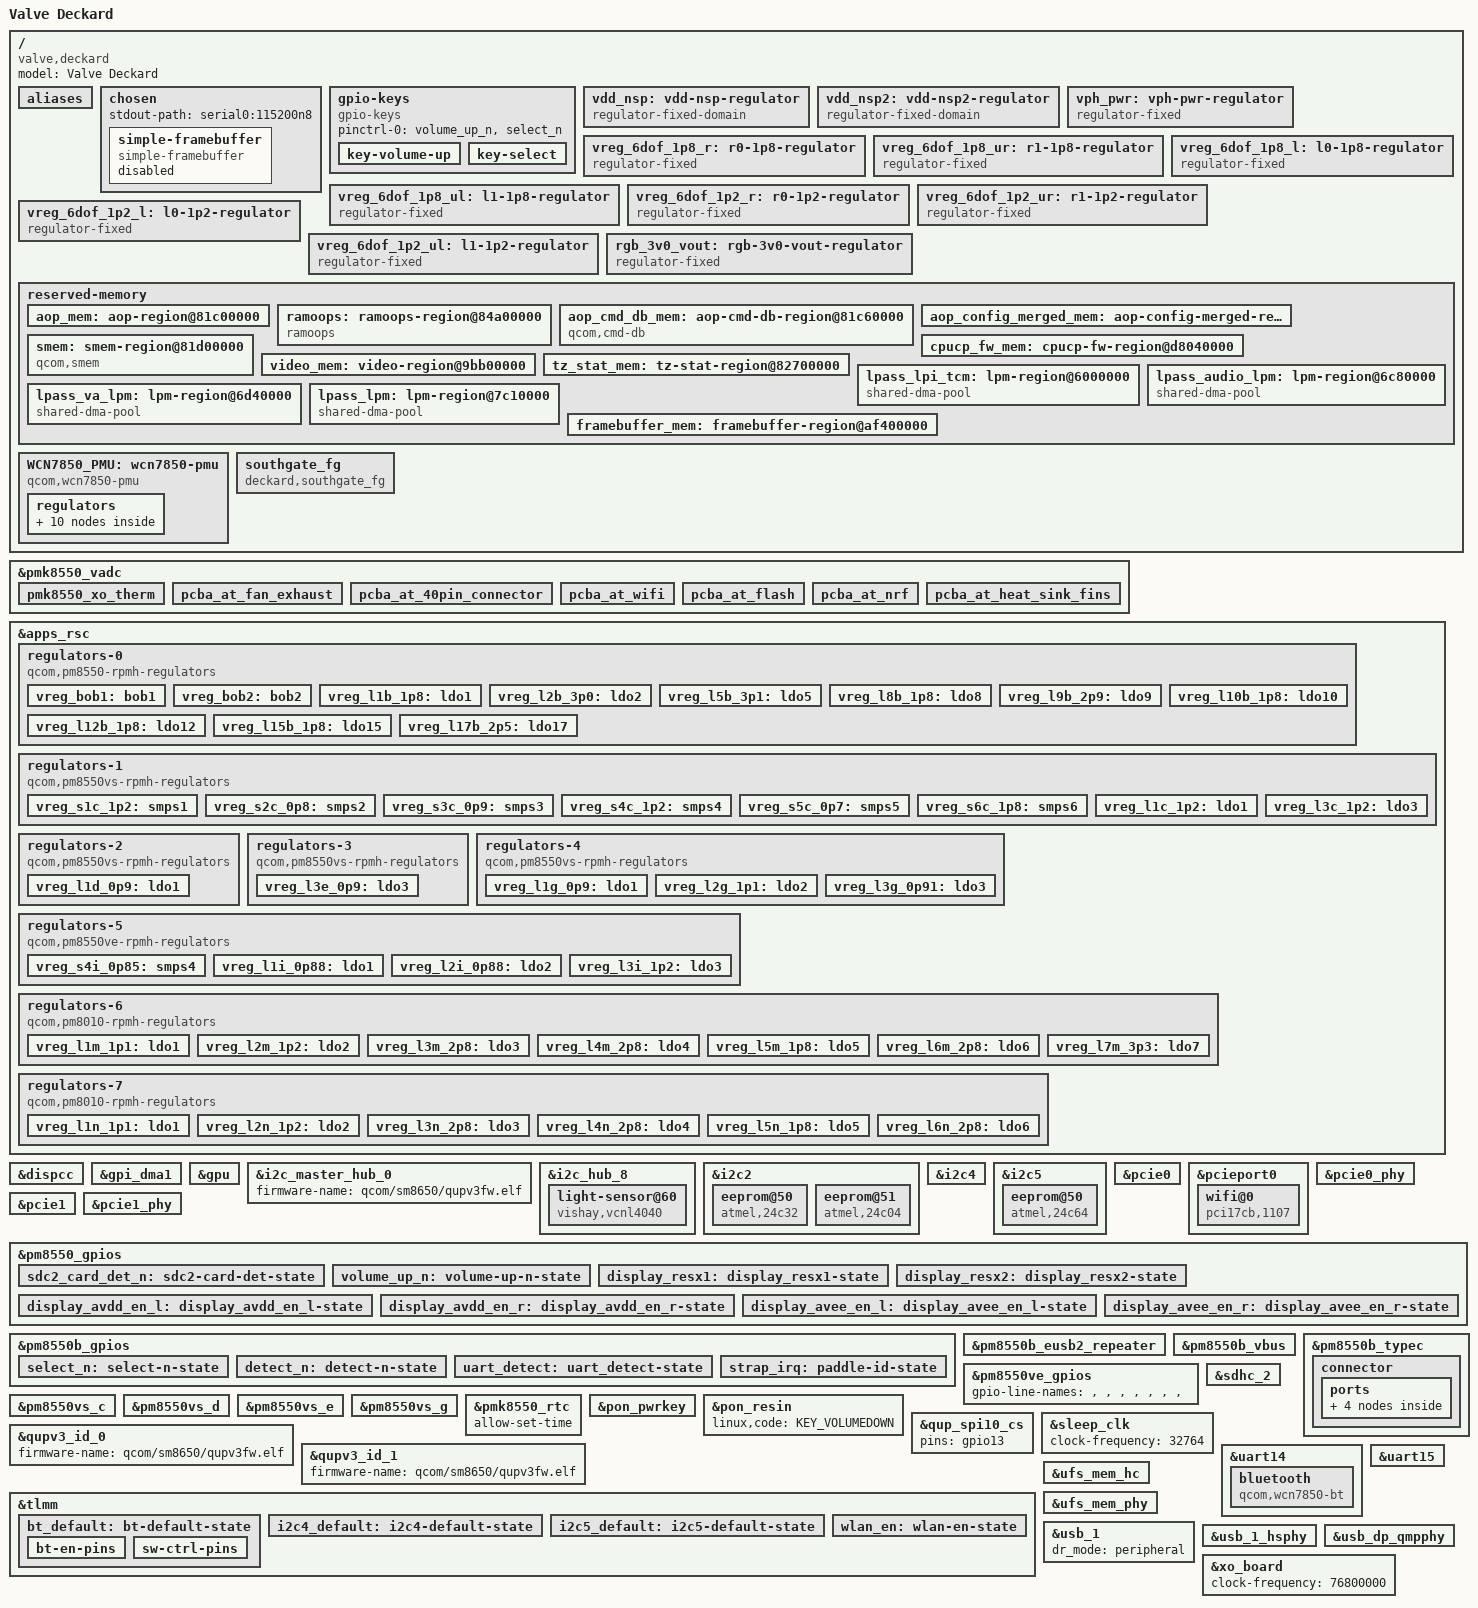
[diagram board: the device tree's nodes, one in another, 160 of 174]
// SPDX-License-Identifier: BSD-3-Clause
/*
 * Copyright (c) 2026, Valve Software
 */

/dts-v1/;

#include <dt-bindings/leds/common.h>
#include <dt-bindings/regulator/qcom,rpmh-regulator.h>
#include <dt-bindings/phy/phy.h>
#include "sm8650.dtsi"
#include "pm8010.dtsi"
#include "pm8550.dtsi"
#include "pm8550b.dtsi"
#include "pm8550vs.dtsi"
#define PMK8550VE_SID 8
#include "pm8550ve.dtsi"
#include "pmk8550.dtsi"

/* Remove nodes incompatible with EL2 */

/delete-node/ &ipa;
/delete-node/ &swr0;
/delete-node/ &swr1;
/delete-node/ &swr2;
/delete-node/ &swr3;
/delete-node/ &lpass_wsa2macro;
/delete-node/ &lpass_rxmacro;
/delete-node/ &lpass_txmacro;
/delete-node/ &lpass_wsamacro;
/delete-node/ &lpass_vamacro;
/delete-node/ &lpass_tlmm;
/delete-node/ &remoteproc_adsp;
/delete-node/ &remoteproc_cdsp;
/delete-node/ &remoteproc_mpss;

/ {
	model = "Valve Deckard";
	compatible = "valve,deckard", "qcom,sm8650";

	aliases {
		serial0 = &uart15;
		serial1 = &uart14;
	};

	chosen {
		stdout-path = "serial0:115200n8";

		simple-framebuffer {
			compatible = "simple-framebuffer";
			width = <4320>;
			height = <2160>;
			stride = <(4320 * 4)>;
			format = "a8r8g8b8";
			memory-region = <&framebuffer_mem>;
			status = "disabled";
		};
	};	

	gpio-keys {
		compatible = "gpio-keys";

		pinctrl-0 = <&volume_up_n>, <&select_n>;
		pinctrl-names = "default";

		key-volume-up {
			label = "Volume Up";
			linux,code = <KEY_VOLUMEUP>;
			gpios = <&pm8550_gpios 6 GPIO_ACTIVE_LOW>;
			debounce-interval = <15>;
			linux,can-disable;
		};

		key-select {
			label = "Select";
			linux,code = <KEY_SELECT>;
			gpios = <&pm8550b_gpios 5 GPIO_ACTIVE_LOW>;
			debounce-interval = <15>;
			linux,can-disable;
		};
	};

	vdd_nsp: vdd-nsp-regulator {
		compatible = "regulator-fixed-domain";
		power-domains = <&rpmhpd RPMHPD_NSP>;
		required-opps = <&rpmhpd_opp_nom>;
		regulator-name = "NSP";
		regulator-always-on;
	};

	vdd_nsp2: vdd-nsp2-regulator {
		compatible = "regulator-fixed-domain";
		power-domains = <&rpmhpd RPMHPD_NSP2>;
		required-opps = <&rpmhpd_opp_nom>;
		regulator-name = "NSP2";
		regulator-always-on;
	};

	vph_pwr: vph-pwr-regulator {
		compatible = "regulator-fixed";

		regulator-name = "vph_pwr";
		regulator-min-microvolt = <3700000>;
		regulator-max-microvolt = <3700000>;

		regulator-always-on;
		regulator-boot-on;
	};

	vreg_6dof_1p8_r: r0-1p8-regulator {
		compatible = "regulator-fixed";
		regulator-name = "vreg_6dof_1p8_r";
		regulator-min-microvolt = <1800000>;
		regulator-max-microvolt = <1800000>;
		gpio = <&tlmm 36 GPIO_ACTIVE_HIGH>;
		vin-supply = <&vreg_l5m_1p8>;
		enable-active-high;
	};

	vreg_6dof_1p8_ur: r1-1p8-regulator {
		compatible = "regulator-fixed";
		regulator-name = "vreg_6dof_1p8_ur";
		regulator-min-microvolt = <1800000>;
		regulator-max-microvolt = <1800000>;
		gpio = <&tlmm 12 GPIO_ACTIVE_HIGH>;
		vin-supply = <&vreg_l5m_1p8>;
		enable-active-high;
	};

	vreg_6dof_1p8_l: l0-1p8-regulator {
		compatible = "regulator-fixed";
		regulator-name = "vreg_6dof_1p8_l";
		regulator-min-microvolt = <1800000>;
		regulator-max-microvolt = <1800000>;
		gpio = <&tlmm 36 GPIO_ACTIVE_HIGH>;
		vin-supply = <&vreg_l5n_1p8>;
		enable-active-high;
	};

	vreg_6dof_1p8_ul: l1-1p8-regulator {
		compatible = "regulator-fixed";
		regulator-name = "vreg_6dof_1p8_ul";
		regulator-min-microvolt = <1800000>;
		regulator-max-microvolt = <1800000>;
		gpio = <&tlmm 12 GPIO_ACTIVE_HIGH>;
		vin-supply = <&vreg_l5n_1p8>;
		enable-active-high;
	};

	vreg_6dof_1p2_r: r0-1p2-regulator {
		compatible = "regulator-fixed";
		regulator-name = "vreg_6dof_1p2_r";
		regulator-min-microvolt = <1200000>;
		regulator-max-microvolt = <1200000>;
		gpio = <&tlmm 37 GPIO_ACTIVE_HIGH>;
		vin-supply = <&vreg_l2m_1p2>;
		enable-active-high;
	};

	vreg_6dof_1p2_ur: r1-1p2-regulator {
		compatible = "regulator-fixed";
		regulator-name = "vreg_6dof_1p2_ur";
		regulator-min-microvolt = <1200000>;
		regulator-max-microvolt = <1200000>;
		gpio = <&tlmm 15 GPIO_ACTIVE_HIGH>;
		vin-supply = <&vreg_l2m_1p2>;
		enable-active-high;
	};

	vreg_6dof_1p2_l: l0-1p2-regulator {
		compatible = "regulator-fixed";
		regulator-name = "vreg_6dof_1p2_l";
		regulator-min-microvolt = <1200000>;
		regulator-max-microvolt = <1200000>;
		gpio = <&tlmm 37 GPIO_ACTIVE_HIGH>;
		vin-supply = <&vreg_l2n_1p2>;
		enable-active-high;
	};

	vreg_6dof_1p2_ul: l1-1p2-regulator {
		compatible = "regulator-fixed";
		regulator-name = "vreg_6dof_1p2_ul";
		regulator-min-microvolt = <1200000>;
		regulator-max-microvolt = <1200000>;
		gpio = <&tlmm 15 GPIO_ACTIVE_HIGH>;
		vin-supply = <&vreg_l2n_1p2>;
		enable-active-high;
	};

	rgb_3v0_vout: rgb-3v0-vout-regulator {
		compatible = "regulator-fixed";
		regulator-name = "exp_rgb_3v0_vout";
		regulator-min-microvolt = <3000000>;
		regulator-max-microvolt = <3000000>;
		gpio = <&tlmm 38 GPIO_ACTIVE_HIGH>;
		detect-gpio = <&pm8550b_gpios 6 GPIO_ACTIVE_HIGH>;
		pinctrl-names = "default";
		pinctrl-0 = <&detect_n>;
		enable-active-high;
		vin-supply = <&vph_pwr>;
	};

	/delete-node/ reserved-memory;

	reserved-memory {
                ranges;

		#address-cells = <2>;
		#size-cells = <2>;

		aop_mem: aop-region@81c00000 {
			no-map;
			reg = <0x0 0x81c00000 0x0 0x60000>;
		};

		ramoops: ramoops-region@84a00000 {
			compatible = "ramoops";
			reg = <0 0x84a00000 0 0x100000>;
			record-size = <0x40000>;
			console-size = <0x40000>;
			pmsg-size = <0x1000>;
			max_reason = <5>;
			ecc-size = <16>;
		};

		aop_cmd_db_mem: aop-cmd-db-region@81c60000 {
			compatible = "qcom,cmd-db";
			reg = <0x0 0x81c60000 0x0 0x20000>;
			no-map;
		};

		/* merged aop_config, tme_crash_dump, tme_log */
		aop_config_merged_mem: aop-config-merged-region@81c80000 {
			//reg = <0x0 0x81c80000 0x0 0x64000>;
			reg = <0x0 0x81c80000 0x0 0x75000>;
			no-map;
		};

		smem: smem-region@81d00000 {
			compatible = "qcom,smem";
			reg = <0x0 0x81d00000 0x0 0x200000>;
			hwlocks = <&tcsr_mutex 3>;
			no-map;
		};

		cpucp_fw_mem: cpucp-fw-region@d8040000 {
			reg = <0x0 0xd8040000 0x0 0x1b2000>;
			no-map;
		};

		video_mem: video-region@9bb00000 {
			reg = <0 0x9bb00000 0 0x800000>;
			no-map;
		};

		tz_stat_mem: tz-stat-region@82700000 {
			reg = <0 0x82700000 0 0x100000>;
			no-map;
		};

		/* 2MB, 8 clocks to power on each 256KB block */
		lpass_lpi_tcm: lpm-region@6000000 {
			compatible = "shared-dma-pool";
			reg = <0 0x06000000 0 0x00200000>;
			no-map;
		};

		/* 64KB, 4 clocks to power on each 16KB block */
		lpass_audio_lpm: lpm-region@6c80000 {
			compatible = "shared-dma-pool";
			reg = <0 0x06c80000 0 0x10000>;
			no-map;
		};

		/* 12KB, 1 clock */
		lpass_va_lpm: lpm-region@6d40000 {
			compatible = "shared-dma-pool";
			reg = <0 0x06d40000 0 0x3000>;
			no-map;
		};

		lpass_lpm: lpm-region@7c10000 {
			compatible = "shared-dma-pool";
			reg = <0 0x07c10000 0 0x8000>;
			no-map;
		};

                framebuffer_mem: framebuffer-region@af400000 {
			reg = <0 0xaf400000 0 0x03000000>;
                        no-map;
                };
        };

	/delete-node/ smp2p-adsp;
	/delete-node/ smp2p-cdsp;
	/delete-node/ smp2p-modem;

	WCN7850_PMU: wcn7850-pmu {
		compatible = "qcom,wcn7850-pmu";

		pinctrl-names = "default";
		pinctrl-0 = <&wlan_en>, <&bt_default>;

		wlan-enable-gpios = <&tlmm 16 GPIO_ACTIVE_HIGH>;
		bt-enable-gpios = <&tlmm 17 GPIO_ACTIVE_HIGH>;

		vdd-supply = <&vreg_s4i_0p85>;
		vddio-supply = <&vreg_l15b_1p8>;
		vddio1p2-supply = <&vreg_l3c_1p2>;
		vddaon-supply = <&vreg_s2c_0p8>;
		vdddig-supply = <&vreg_s3c_0p9>;
		vddrfa1p2-supply = <&vreg_s1c_1p2>;
		vddrfa1p8-supply = <&vreg_s6c_1p8>;

		clocks = <&rpmhcc RPMH_RF_CLK1>;

		regulators {
			vreg_pmu_rfa_cmn: ldo0 {
				regulator-name = "vreg_pmu_rfa_cmn";
			};

			vreg_pmu_aon_0p59: ldo1 {
				regulator-name = "vreg_pmu_aon_0p59";
			};

			vreg_pmu_wlcx_0p8: ldo2 {
				regulator-name = "vreg_pmu_wlcx_0p8";
			};

			vreg_pmu_wlmx_0p85: ldo3 {
				regulator-name = "vreg_pmu_wlmx_0p85";
			};

			vreg_pmu_btcmx_0p85: ldo4 {
				regulator-name = "vreg_pmu_btcmx_0p85";
			};

			vreg_pmu_rfa_0p8: ldo5 {
				regulator-name = "vreg_pmu_rfa_0p8";
			};

			vreg_pmu_rfa_1p2: ldo6 {
				regulator-name = "vreg_pmu_rfa_1p2";
			};

			vreg_pmu_rfa_1p8: ldo7 {
				regulator-name = "vreg_pmu_rfa_1p8";
			};

			vreg_pmu_pcie_0p9: ldo8 {
				regulator-name = "vreg_pmu_pcie_0p9";
			};

			vreg_pmu_pcie_1p8: ldo9 {
				regulator-name = "vreg_pmu_pcie_1p8";
			};
		};
	};

	southgate_fg {
		compatible = "deckard,southgate_fg";
		status="okay";
		io-channels = <&pmk8550_vadc PM8550B_ADC5_GEN3_VBAT_SNS_CHGR(7)>,
					  <&pmk8550_vadc PM8550B_ADC5_GEN3_ICHG_FB(7)>;
		io-channel-names = "vbat", "ibat";
	};
};


&pmk8550_vadc {
	// NOTE TODO REVISIT - There is some chance to lower interrupt usage slightly if these are converted to thermal zones and qcom,adc-tm-type is set appropriately..

	// NOTE Setting qcom,adc-tm-type errors out driver and blocks all channels with obscure error. Need Thermal Zone setup to match.
	pmk8550_xo_therm {
		reg = <PMK8550_ADC5_GEN3_AMUX_THM1_XO_THERM_100K_PU(0)>;
		label = "pmk8550_xo_therm";
		qcom,ratiometric;
		qcom,hw-settle-time = <200>;
		qcom,pre-scaling = <1 1>;
	};


	/* External PM8550 Thermistors */
	// 200 us measured on POC-F Boards as required time to reach stability.
	pcba_at_fan_exhaust {
		// Quiet Therm RT0502
		reg = <PM8550_ADC5_GEN3_AMUX_THM1_100K_PU(1)>;
		label = "pcba_at_fan_exhaust";
		qcom,hw-settle-time = <200>;
		qcom,ratiometric;
	};

	pcba_at_40pin_connector {
		// SDM SKIN Therm RT507
		reg = <PM8550_ADC5_GEN3_AMUX_THM2_100K_PU(1)>;
		label = "pcba_at_40pin_connector";
		qcom,hw-settle-time = <200>;
		qcom,ratiometric;
	};

	pcba_at_wifi {
		// WLAN Therm RT0503
		reg = <PM8550_ADC5_GEN3_AMUX_THM3_100K_PU(1)>;
		label = "pcba_at_wifi";
		qcom,hw-settle-time = <200>;
		qcom,ratiometric;
	};

	pcba_at_flash {
		// ADC_1 Therm RT506
		reg = <PM8550_ADC5_GEN3_AMUX_THM4_100K_PU(1)>;
		label = "pcba_at_flash";
		qcom,hw-settle-time = <200>;
		qcom,ratiometric;
	};

	pcba_at_nrf {
		// ADC_2 Therm RT505
		reg = <PM8550_ADC5_GEN3_AMUX_THM5_100K_PU(1)>;
		label = "pcba_at_nrf";
		qcom,hw-settle-time = <200>;
		qcom,ratiometric;
	};


	/* External PM8550B Thermistors */
	pcba_at_heat_sink_fins {
		reg = <PM8550B_ADC5_GEN3_AMUX_THM4_USB_THERM_100K_PU(7)>;
		label = "pcba_at_heat_sink_fins";
		qcom,hw-settle-time = <200>;
		qcom,ratiometric;
	};
};

&apps_rsc {
	regulators-0 {
		compatible = "qcom,pm8550-rpmh-regulators";

		vdd-bob1-supply = <&vph_pwr>;
		vdd-bob2-supply = <&vph_pwr>;
		vdd-l1-l4-l10-supply = <&vreg_s6c_1p8>;
		vdd-l2-l13-l14-supply = <&vreg_bob1>;
		vdd-l3-supply = <&vreg_s1c_1p2>;
		vdd-l5-l16-supply = <&vreg_bob1>;
		vdd-l8-l9-supply = <&vreg_bob1>;
		vdd-l12-supply = <&vreg_s6c_1p8>;
		vdd-l15-supply = <&vreg_s6c_1p8>;
		vdd-l17-supply = <&vreg_bob2>;

		qcom,pmic-id = "b";

		vreg_bob1: bob1 {
			regulator-name = "vreg_bob1";
			regulator-min-microvolt = <3296000>; // note: min is 3008000, init is 3296000
			regulator-max-microvolt = <3960000>;
			regulator-initial-mode = <RPMH_REGULATOR_MODE_HPM>;
		};

		vreg_bob2: bob2 {
			regulator-name = "vreg_bob2";
			regulator-min-microvolt = <2720000>; // note: min is 2704000, init is 2720000
			regulator-max-microvolt = <3008000>;
			regulator-initial-mode = <RPMH_REGULATOR_MODE_HPM>;

			regulator-always-on; // XXX USB HS, SBU MUX
		};

		vreg_l1b_1p8: ldo1 {
			regulator-name = "vreg_l1b_1p8";
			regulator-min-microvolt = <1800000>;
			regulator-max-microvolt = <1800000>;
			regulator-initial-mode = <RPMH_REGULATOR_MODE_HPM>;

			regulator-always-on; // XXX sensors
		};

		vreg_l2b_3p0: ldo2 {
			regulator-name = "vreg_l2b_3p0";
			regulator-min-microvolt = <3008000>;
			regulator-max-microvolt = <3008000>;
			regulator-initial-mode = <RPMH_REGULATOR_MODE_HPM>;

			regulator-always-on; // XXX sensors
		};

		vreg_l5b_3p1: ldo5 {
			regulator-name = "vreg_l5b_3p1";
			regulator-min-microvolt = <3104000>;
			regulator-max-microvolt = <3104000>;
			regulator-initial-mode = <RPMH_REGULATOR_MODE_HPM>;
			regulator-allow-set-load;
			regulator-allowed-modes = <RPMH_REGULATOR_MODE_LPM
						   RPMH_REGULATOR_MODE_HPM>;
			regulator-always-on; // XXX SBU MUX
		};

		vreg_l8b_1p8: ldo8 {
			regulator-name = "vreg_l8b_1p8";
			regulator-min-microvolt = <1800000>;
			regulator-max-microvolt = <1800000>;
			regulator-initial-mode = <RPMH_REGULATOR_MODE_HPM>;
			regulator-allow-set-load;
			regulator-allowed-modes = <RPMH_REGULATOR_MODE_LPM
						   RPMH_REGULATOR_MODE_HPM>;
		};

		vreg_l9b_2p9: ldo9 {
			regulator-name = "vreg_l9b_2p9";
			regulator-min-microvolt = <2960000>;
			regulator-max-microvolt = <2960000>;
			regulator-initial-mode = <RPMH_REGULATOR_MODE_HPM>;
			regulator-allow-set-load;
			regulator-allowed-modes = <RPMH_REGULATOR_MODE_LPM
						   RPMH_REGULATOR_MODE_HPM>;
		};

		vreg_l10b_1p8: ldo10 {
			regulator-name = "vreg_l10b_1p8";
			regulator-min-microvolt = <1800000>;
			regulator-max-microvolt = <1800000>;
			regulator-initial-mode = <RPMH_REGULATOR_MODE_HPM>;

			regulator-always-on; // XXX DMIC
		};

		vreg_l12b_1p8: ldo12 {
			regulator-name = "vreg_l12b_1p8";
			regulator-min-microvolt = <1800000>;
			regulator-max-microvolt = <1800000>;
			regulator-initial-mode = <RPMH_REGULATOR_MODE_HPM>;
			regulator-allow-set-load;
			regulator-allowed-modes = <RPMH_REGULATOR_MODE_LPM
						   RPMH_REGULATOR_MODE_HPM>;
		};

		vreg_l15b_1p8: ldo15 {
			regulator-name = "vreg_l15b_1p8";
			regulator-min-microvolt = <1800000>;
			regulator-max-microvolt = <1800000>;
			regulator-initial-mode = <RPMH_REGULATOR_MODE_HPM>;
			regulator-allow-set-load;
			regulator-allowed-modes = <RPMH_REGULATOR_MODE_LPM
						   RPMH_REGULATOR_MODE_HPM>;
			regulator-always-on; // XXX: 1.8V pull ups
		};

		vreg_l17b_2p5: ldo17 {
			regulator-name = "vreg_l17b_2p5";
			regulator-min-microvolt = <2504000>;
			regulator-max-microvolt = <2504000>;
			regulator-initial-mode = <RPMH_REGULATOR_MODE_HPM>;
			regulator-allow-set-load;
			regulator-allowed-modes = <RPMH_REGULATOR_MODE_LPM
						   RPMH_REGULATOR_MODE_HPM>;
		};
	};

	regulators-1 {
		compatible = "qcom,pm8550vs-rpmh-regulators";

		vdd-l1-supply = <&vreg_s1c_1p2>;
		vdd-l3-supply = <&vreg_s1c_1p2>;
		vdd-s1-supply = <&vph_pwr>;
		vdd-s2-supply = <&vph_pwr>;
		vdd-s3-supply = <&vph_pwr>;
		vdd-s4-supply = <&vph_pwr>;
		vdd-s5-supply = <&vph_pwr>;
		vdd-s6-supply = <&vph_pwr>;

		qcom,pmic-id = "c";

		vreg_s1c_1p2: smps1 {
			regulator-name = "vreg_s1c_1p2";
			regulator-min-microvolt = <1224000>;
			regulator-max-microvolt = <1348000>;
			// init 1256000
			regulator-initial-mode = <RPMH_REGULATOR_MODE_HPM>;

			regulator-always-on; // USB, UFS?
		};

		vreg_s2c_0p8: smps2 {
			regulator-name = "vreg_s2c_0p8";
			regulator-min-microvolt = <500000>;
			regulator-max-microvolt = <1036000>;
			// init 852000
			regulator-initial-mode = <RPMH_REGULATOR_MODE_HPM>;
		};

		vreg_s3c_0p9: smps3 {
			regulator-name = "vreg_s3c_0p9";
			regulator-min-microvolt = <904000>;
			regulator-max-microvolt = <1064000>;
			// init 976000
			regulator-initial-mode = <RPMH_REGULATOR_MODE_HPM>;
		};

		vreg_s4c_1p2: smps4 {
			regulator-name = "vreg_s4c_1p2";
			regulator-min-microvolt = <1200000>;
			regulator-max-microvolt = <1280000>;
			// init 1224000
			regulator-initial-mode = <RPMH_REGULATOR_MODE_HPM>;
		};

		vreg_s5c_0p7: smps5 {
			regulator-name = "vreg_s5c_0p7";
			regulator-min-microvolt = <300000>;
			regulator-max-microvolt = <900000>;
			// init 752000
			regulator-initial-mode = <RPMH_REGULATOR_MODE_HPM>;
		};

		vreg_s6c_1p8: smps6 {
			regulator-name = "vreg_s6c_1p8";
			regulator-min-microvolt = <1856000>;
			regulator-max-microvolt = <2000000>;
			// init 1856000
			regulator-initial-mode = <RPMH_REGULATOR_MODE_HPM>;
		};

		vreg_l1c_1p2: ldo1 {
			regulator-name = "vreg_l1c_1p2";
			regulator-min-microvolt = <1200000>; // note: min 1100000
			regulator-max-microvolt = <1200000>;
			regulator-initial-mode = <RPMH_REGULATOR_MODE_HPM>;
		};

		vreg_l3c_1p2: ldo3 {
			regulator-name = "vreg_l3c_1p2";
			regulator-min-microvolt = <1200000>;
			regulator-max-microvolt = <1200000>;
			regulator-initial-mode = <RPMH_REGULATOR_MODE_HPM>;
			regulator-allow-set-load;
			regulator-allowed-modes = <RPMH_REGULATOR_MODE_LPM
						   RPMH_REGULATOR_MODE_HPM>;
			regulator-always-on; // XXX: 1.2V pull ups
		};
	};

	regulators-2 {
		compatible = "qcom,pm8550vs-rpmh-regulators";
		qcom,pmic-id = "d";

		vdd-l1-supply = <&vreg_s3c_0p9>;

		vreg_l1d_0p9: ldo1 {
			regulator-name = "vreg_l1d_0p9";
			regulator-min-microvolt = <912000>; // note: min 880000
			regulator-max-microvolt = <920000>;
			regulator-initial-mode = <RPMH_REGULATOR_MODE_HPM>;
			regulator-allow-set-load;
			regulator-allowed-modes = <RPMH_REGULATOR_MODE_LPM
						   RPMH_REGULATOR_MODE_HPM>;
		};
	};

	regulators-3 {
		compatible = "qcom,pm8550vs-rpmh-regulators";

		vdd-l3-supply = <&vreg_s3c_0p9>;

		qcom,pmic-id = "e";

		vreg_l3e_0p9: ldo3 {
			regulator-name = "vreg_l3e_0p9";
			regulator-min-microvolt = <880000>;
			regulator-max-microvolt = <920000>;
			regulator-initial-mode = <RPMH_REGULATOR_MODE_HPM>;
			regulator-allow-set-load;
			regulator-allowed-modes = <RPMH_REGULATOR_MODE_LPM
						   RPMH_REGULATOR_MODE_HPM>;
		};
	};

	regulators-4 {
		compatible = "qcom,pm8550vs-rpmh-regulators";

		vdd-l1-supply = <&vreg_s3c_0p9>;
		vdd-l2-supply = <&vreg_s1c_1p2>;
		vdd-l3-supply = <&vreg_s3c_0p9>;

		qcom,pmic-id = "g";

		vreg_l1g_0p9: ldo1 {
			regulator-name = "vreg_l1g_0p9";
			regulator-min-microvolt = <912000>;
			regulator-max-microvolt = <920000>;
			regulator-initial-mode = <RPMH_REGULATOR_MODE_HPM>;
			// QLINK ?
		};

		vreg_l2g_1p1: ldo2 {
			regulator-name = "vreg_l2g_1p1";
			regulator-min-microvolt = <1104000>;
			regulator-max-microvolt = <1104000>;
			regulator-initial-mode = <RPMH_REGULATOR_MODE_HPM>;
		};

		vreg_l3g_0p91: ldo3 {
			regulator-name = "vreg_l3g_0p91";
			regulator-min-microvolt = <880000>;
			regulator-max-microvolt = <912000>;
			regulator-initial-mode = <RPMH_REGULATOR_MODE_HPM>;
		};
	};

	regulators-5 {
		compatible = "qcom,pm8550ve-rpmh-regulators";

		vdd-l1-supply = <&vreg_s3c_0p9>;
		vdd-l2-supply = <&vreg_s3c_0p9>;
		vdd-l3-supply = <&vreg_s1c_1p2>;
		vdd-s4-supply = <&vph_pwr>;

		qcom,pmic-id = "i";

		vreg_s4i_0p85: smps4 {
			regulator-name = "vreg_s4i_0p85";
			regulator-min-microvolt = <852000>;
			regulator-max-microvolt = <1004000>;
			// init 852000
			regulator-initial-mode = <RPMH_REGULATOR_MODE_HPM>;
		};

		vreg_l1i_0p88: ldo1 {
			regulator-name = "vreg_l1i_0p88";
			regulator-min-microvolt = <880000>;
			regulator-max-microvolt = <912000>;
			regulator-initial-mode = <RPMH_REGULATOR_MODE_HPM>;
			regulator-allow-set-load;
			regulator-allowed-modes = <RPMH_REGULATOR_MODE_LPM
						   RPMH_REGULATOR_MODE_HPM>;
		};

		vreg_l2i_0p88: ldo2 {
			regulator-name = "vreg_l2i_0p88";
			regulator-min-microvolt = <880000>;
			regulator-max-microvolt = <912000>;
			regulator-initial-mode = <RPMH_REGULATOR_MODE_HPM>;
			regulator-allow-set-load;
			regulator-allowed-modes = <RPMH_REGULATOR_MODE_LPM
						   RPMH_REGULATOR_MODE_HPM>;
		};

		vreg_l3i_1p2: ldo3 {
			regulator-name = "vreg_l3i_1p2";
			regulator-min-microvolt = <1200000>;
			regulator-max-microvolt = <1200000>;
			regulator-initial-mode = <RPMH_REGULATOR_MODE_HPM>;
			regulator-allow-set-load;
			regulator-allowed-modes = <RPMH_REGULATOR_MODE_LPM
						   RPMH_REGULATOR_MODE_HPM>;
		};
	};

	regulators-6 {
		compatible = "qcom,pm8010-rpmh-regulators";
		qcom,pmic-id = "m";

		vdd-l1-l2-supply = <&vreg_s1c_1p2>;
		vdd-l3-l4-supply = <&vreg_bob2>;
		vdd-l5-supply = <&vreg_s6c_1p8>;
		vdd-l6-supply = <&vreg_bob2>;
		vdd-l7-supply = <&vreg_bob1>;

		vreg_l1m_1p1: ldo1 {
			regulator-name = "vreg_l1m_1p1";
			regulator-min-microvolt = <1104000>;
			regulator-max-microvolt = <1104000>;
			regulator-initial-mode = <RPMH_REGULATOR_MODE_HPM>;
			regulator-allow-set-load;
			regulator-allowed-modes = <RPMH_REGULATOR_MODE_LPM
						   RPMH_REGULATOR_MODE_HPM>;
		};

		vreg_l2m_1p2: ldo2 {
			regulator-name = "vreg_l2m_1p2";
			regulator-min-microvolt = <1200000>;
			regulator-max-microvolt = <1200000>;
			regulator-initial-mode = <RPMH_REGULATOR_MODE_HPM>;
			regulator-allow-set-load;
			regulator-allowed-modes = <RPMH_REGULATOR_MODE_LPM
						   RPMH_REGULATOR_MODE_HPM>;
		};

		vreg_l3m_2p8: ldo3 {
			regulator-name = "vreg_l3m_2p8";
			regulator-min-microvolt = <2800000>;
			regulator-max-microvolt = <2800000>;
			regulator-initial-mode = <RPMH_REGULATOR_MODE_HPM>;
		};

		vreg_l4m_2p8: ldo4 {
			regulator-name = "vreg_l4m_2p8";
			regulator-min-microvolt = <2800000>;
			regulator-max-microvolt = <2800000>;
			regulator-initial-mode = <RPMH_REGULATOR_MODE_HPM>;
		};

		vreg_l5m_1p8: ldo5 {
			regulator-name = "vreg_l5m_1p8";
			regulator-min-microvolt = <1800000>;
			regulator-max-microvolt = <1800000>;
			regulator-initial-mode = <RPMH_REGULATOR_MODE_HPM>;
		};

		vreg_l6m_2p8: ldo6 {
			regulator-name = "vreg_l6m_2p8";
			regulator-min-microvolt = <2800000>;
			regulator-max-microvolt = <2800000>;
			regulator-initial-mode = <RPMH_REGULATOR_MODE_HPM>;
		};

		vreg_l7m_3p3: ldo7 {
			regulator-name = "vreg_l7m_3p3";
			regulator-min-microvolt = <3304000>;
			regulator-max-microvolt = <3304000>;
			regulator-initial-mode = <RPMH_REGULATOR_MODE_HPM>;

			regulator-always-on;
		};
	};

	regulators-7 {
		compatible = "qcom,pm8010-rpmh-regulators";
		qcom,pmic-id = "n";

		vdd-l1-l2-supply = <&vreg_s1c_1p2>;
		vdd-l3-l4-supply = <&vreg_bob2>;
		vdd-l5-supply = <&vreg_s6c_1p8>;
		vdd-l6-supply = <&vreg_bob2>;

		vreg_l1n_1p1: ldo1 {
			regulator-name = "vreg_l1n_1p1";
			regulator-min-microvolt = <1104000>;
			regulator-max-microvolt = <1104000>;
			regulator-initial-mode = <RPMH_REGULATOR_MODE_HPM>;
			regulator-allow-set-load;
			regulator-allowed-modes = <RPMH_REGULATOR_MODE_LPM
						   RPMH_REGULATOR_MODE_HPM>;
		};

		vreg_l2n_1p2: ldo2 {
			regulator-name = "vreg_l2n_1p2";
			regulator-min-microvolt = <1200000>;
			regulator-max-microvolt = <1200000>;
			regulator-initial-mode = <RPMH_REGULATOR_MODE_HPM>;
			regulator-allow-set-load;
			regulator-allowed-modes = <RPMH_REGULATOR_MODE_LPM
						   RPMH_REGULATOR_MODE_HPM>;
		};

		vreg_l3n_2p8: ldo3 {
			regulator-name = "vreg_l3n_2p8";
			regulator-min-microvolt = <2800000>;
			regulator-max-microvolt = <2800000>;
			regulator-initial-mode = <RPMH_REGULATOR_MODE_HPM>;
		};

		vreg_l4n_2p8: ldo4 {
			regulator-name = "vreg_l4n_2p8";
			regulator-min-microvolt = <2800000>;
			regulator-max-microvolt = <2800000>;
			regulator-initial-mode = <RPMH_REGULATOR_MODE_HPM>;
		};

		vreg_l5n_1p8: ldo5 {
			regulator-name = "vreg_l5n_1p8";
			regulator-min-microvolt = <1800000>;
			regulator-max-microvolt = <1800000>;
			regulator-initial-mode = <RPMH_REGULATOR_MODE_HPM>;
		};

		vreg_l6n_2p8: ldo6 {
			regulator-name = "vreg_l6n_2p8";
			regulator-min-microvolt = <2800000>;
			regulator-max-microvolt = <2800000>;
			regulator-initial-mode = <RPMH_REGULATOR_MODE_HPM>;
		};
	};
};

&dispcc {
	status = "okay";
};

&gpi_dma1 {
	status = "okay";
};

&gpu {
	/delete-node/ zap-shader;
};

&i2c_master_hub_0 {
	firmware-name = "qcom/sm8650/qupv3fw.elf";

	status = "okay";
};

// Prox Sensor I2C
&i2c_hub_8 {
	status = "okay";

	light-sensor@60 {
		compatible = "vishay,vcnl4040";
		reg = <0x60>;
		proximity-near-level = <220>;

		vin0-supply = <&vreg_l2b_3p0>; 
		vin1-supply = <&vreg_l15b_1p8>; 

		proximity-integration-time = <800>; // microseconds
		proximity-multi-pulse = <1>;

		status = "okay";
	};
};

&i2c2 {
	status = "okay";
	
	// PADDLE EEPROM
	eeprom@50 {
		compatible  = "atmel,24c32";
		status      = "okay";
		label		= "strap_eeprom";
		reg         = <0x50>;
		//wp-gpios = <&tlmm 78 GPIO_ACTIVE_HIGH>;
		vcc-supply  = <&vreg_l15b_1p8>;
	};

	// PADDLE EEPROM - 256 Bytes on 0x51 added in EV3.3
	eeprom@51 {
		compatible  = "atmel,24c04";
		status      = "okay";
		label       = "strap_v2_eeprom";
		reg         = <0x51>;
		vcc-supply  = <&vreg_l15b_1p8>;
	};
};

&i2c4 {
	status = "okay";
};

&i2c5 {
	status = "okay";

	// BOOT EEPROM
	eeprom@50 {
		compatible  = "atmel,24c64";
		status      = "okay";
		label		= "core_v2_eeprom";
		reg         = <0x50>;
		pagesize    = <32>;
		size        = <8192>;
		address-width = <16>;
		wp-gpios = <&tlmm 78 GPIO_ACTIVE_HIGH>;
		vcc-supply  = <&vreg_l15b_1p8>;
	};

};

&pcie0 {
	wake-gpios = <&tlmm 96 GPIO_ACTIVE_HIGH>;
	perst-gpios = <&tlmm 94 GPIO_ACTIVE_LOW>;

	pinctrl-0 = <&pcie0_default_state>;
	pinctrl-names = "default";

	status = "okay";
};

&pcieport0 {
	wifi@0 {
		compatible = "pci17cb,1107";
		reg = <0x10000 0x0 0x0 0x0 0x0>;

		vddrfacmn-supply = <&vreg_pmu_rfa_cmn>;
		vddaon-supply = <&vreg_pmu_aon_0p59>;
		vddwlcx-supply = <&vreg_pmu_wlcx_0p8>;
		vddwlmx-supply = <&vreg_pmu_wlmx_0p85>;
		vddrfa0p8-supply = <&vreg_pmu_rfa_0p8>;
		vddrfa1p2-supply = <&vreg_pmu_rfa_1p2>;
		vddrfa1p8-supply = <&vreg_pmu_rfa_1p8>;
		vddpcie0p9-supply = <&vreg_pmu_pcie_0p9>;
		vddpcie1p8-supply = <&vreg_pmu_pcie_1p8>;

		qcom,default-bdf = "board_77.bin";
	};
};

&pcie0_phy {
	vdda-phy-supply = <&vreg_l1i_0p88>;
	vdda-pll-supply = <&vreg_l3i_1p2>;

	status = "okay";
};

&pcie1 {
	vdda-supply = <&vph_pwr>;
	vddpe-3v3-supply = <&vph_pwr>; // XXX

	wake-gpios = <&tlmm 99 GPIO_ACTIVE_HIGH>;
	perst-gpios = <&tlmm 97 GPIO_ACTIVE_LOW>;

	pinctrl-0 = <&pcie1_default_state>;
	pinctrl-names = "default";

	status = "okay";
};

&pcie1_phy {
	vdda-phy-supply = <&vreg_l3e_0p9>;
	vdda-pll-supply = <&vreg_l3i_1p2>;
	vdda-qref-supply = <&vreg_l1i_0p88>;

	status = "okay";
};

// For 1.8V operation on PM8550
// VIN0 ( 0 ) for GPIO_01 to GPIO_04
// VIN1 ( 1 ) for GPIO_05 to GPIO_12 ( except 7 )
&pm8550_gpios {
	sdc2_card_det_n: sdc2-card-det-state {
		pins = "gpio12";
		function = "normal";
		bias-pull-up;
		input-enable;
		output-disable;
		power-source = <1>; /* 1.8 V */
	};

	volume_up_n: volume-up-n-state {
		pins = "gpio6";
		function = "normal";
		bias-pull-up;
		input-enable;
		power-source = <1>;
	};

	display_resx1: display_resx1-state {
		pins = "gpio3";
		function = "normal";
		power-source = <1>; /* 1.8 V */
	};

	display_resx2: display_resx2-state {
		pins = "gpio11";
		function = "normal";
		power-source = <1>; /* 1.8 V */
	};

	display_avdd_en_l: display_avdd_en_l-state {
		pins = "gpio4";
		function = "normal";
		power-source = <0>; /* 1.8 V */
	};

	display_avdd_en_r: display_avdd_en_r-state {
		pins = "gpio8";
		function = "normal";
		power-source = <1>; /* 1.8 V */
	};

	display_avee_en_l: display_avee_en_l-state {
		pins = "gpio9";
		function = "normal";
		power-source = <0>; /* 1.8 V */
	};

	display_avee_en_r: display_avee_en_r-state {
		pins = "gpio10";
		function = "normal";
		power-source = <0>; /* 1.8 V */
	};
};

&pm8550b_gpios {
	select_n: select-n-state {
		pins = "gpio5";
		function = "normal";
		power-source = <1>;
		bias-pull-up;
		input-enable;
	};

	detect_n: detect-n-state {
		pins = "gpio6";
		function = "normal";
		power-source = <1>;
		bias-pull-up;
		input-enable;
	};

	uart_detect: uart_detect-state {
		pins = "gpio7";
		function = "normal";
		power-source = <1>;
	};

	strap_irq: paddle-id-state {
		pins = "gpio10";
		function = "normal";
		bias-pull-up;
		input-enable;
	};
};

&pm8550b_eusb2_repeater {
	vdd18-supply = <&vreg_l15b_1p8>;
	vdd3-supply = <&vreg_l5b_3p1>;
};

&pm8550b_vbus {
	status = "okay";
};

&pm8550b_typec {
	status = "okay";

	vdd-pdphy-supply = <&vreg_l5b_3p1>;

	io-channels = <&pmk8550_vadc PM8550B_ADC5_GEN3_VBAT_SNS_CHGR(7)>,
				  <&pmk8550_vadc PM8550B_ADC5_GEN3_VBAT_2S_MID_CHGR(7)>;
	io-channel-names = "vbat", "vmid";

	connector {
		power-role = "dual";
		data-role = "dual";
		try-power-role = "sink";
		source-pdos = <PDO_FIXED(5000, 1500, PDO_FIXED_DUAL_ROLE | PDO_FIXED_DATA_SWAP | PDO_FIXED_USB_COMM)>;
		sink-pdos = <PDO_FIXED(5000, 300, PDO_FIXED_DUAL_ROLE | PDO_FIXED_DATA_SWAP |  PDO_FIXED_USB_COMM)>;
		op-sink-microwatt = <15000000>;

		ports {
			#address-cells = <1>;
			#size-cells = <0>;

			port@0 {
				reg = <0>;

				pm8550b_role_switch_out: endpoint {
					remote-endpoint = <&usb_1_dwc3_hs>;
				};
			};

			port@1 {
				reg = <1>;

				tcpm_sbu_out: endpoint {
					remote-endpoint = <&sbu_mux_in>;
				};
			};

#if 0
			port@2 {
				reg = <2>;

				dp_mode_out: endpoint {
					remote-endpoint = <&dp_mode>;
				};
			};


			port@1 {
				reg = <1>;

				pm8550b_typec_mux_out: endpoint {
					remote-endpoint = <&usb_1_qmpphy_typec_mux_in>;
				};
			};
#endif
		};
	};

};

&pm8550ve_gpios {
	gpio-line-names =
		// GPIO01 - GPIO08
		"",  "",  "",  "",  "",  "",  "",  "";
};

&pm8550vs_c {
	status = "okay";
};

&pm8550vs_d {
	status = "okay";
};

&pm8550vs_e {
	status = "okay";
};

&pm8550vs_g {
	status = "okay";
};

&pmk8550_rtc {
	status = "okay";
	allow-set-time;
};

&pon_pwrkey {
	status = "okay";
};

&pon_resin {
	linux,code = <KEY_VOLUMEDOWN>;

	status = "okay";
};

&qup_spi10_cs {
	pins = "gpio13";
};

&qupv3_id_0 {
	firmware-name = "qcom/sm8650/qupv3fw.elf";

	status = "okay";
};

&qupv3_id_1 {
	firmware-name = "qcom/sm8650/qupv3fw.elf";

	status = "okay";
};

&sdhc_2 {
	cd-gpios = <&pm8550_gpios 12 GPIO_ACTIVE_LOW>;

	vmmc-supply = <&vreg_l9b_2p9>;
	vqmmc-supply = <&vreg_l8b_1p8>; // actually level shifter
	bus-width = <4>;
	no-sdio;
	no-mmc;

	pinctrl-0 = <&sdc2_default>, <&sdc2_card_det_n>;
	pinctrl-1 = <&sdc2_sleep>, <&sdc2_card_det_n>;
	pinctrl-names = "default", "sleep";

	status = "okay";
};

&sleep_clk {
	clock-frequency = <32764>;
};

&tlmm {
	gpio-line-names =
		// GPIO000 - GPIO015
		"",  "",  "",  "",  "",  "",  "",  "fpga_rst",  "",  "",  "",  "nrf_time_sync",  "",  "",  "",  "",
		// GPIO016 - GPIO031
		"",  "",  "",  "",  "",  "",  "",  "",  "",  "",  "",  "",  "",  "",  "",  "",
		// GPIO032 - GPIO047
		"",  "",  "",  "fpga_spi_cs",  "",  "",  "",  "fpga_crst",  "",  "",  "",  "",  "",  "",  "",  "",
		// GPIO048 - GPIO063
		"",  "",  "nrf_swdio",  "nrf_swclk",  "",  "",  "",  "",  "fpga_cam0_strobe",  "fpga_cam1_strobe",  "",  "",  "",  "",  "",  "",
		// GPIO064 - GPIO079
		"",  "",  "",  "",  "",  "",  "",  "",  "",  "",  "",  "",  "",  "",  "",  "",
		// GPIO080 - GPIO095
		"",  "",  "",  "",  "",  "",  "",  "",  "",  "",  "",  "",  "",  "",  "",  "",
		// GPIO096 - GPIO111
		"",  "",  "",  "",  "",  "",  "",  "",  "",  "",  "",  "",  "",  "",  "fpga_cam1_frame_sync",  "",
		// GPIO112 - GPIO127
		"",  "",  "",  "",  "",  "",  "",  "",  "",  "",  "",  "",  "fpga_cam0_frame_sync",  "",  "",  "",
		// GPIO128 - GPIO143
		"",  "",  "",  "",  "",  "",  "",  "",  "",  "",  "",  "",  "",  "",  "",  "",
		// GPIO144 - GPIO159
		"",  "",  "",  "",  "",  "",  "",  "",  "",  "",  "",  "fpga_cdone",  "",  "",  "fpga_cready",  "",
		// GPIO160 - GPIO175
		"",  "",  "te2_left",  "",  "nrf_reset",  "",  "",  "",  "",  "",  "",  "",  "",  "",  "",  "",
		// GPIO176 - GPIO189
		"",  "",  "te2_right",  "",  "", "", "", "", "", "", "", "", "", "";

	bt_default: bt-default-state {
		bt-en-pins {
			pins = "gpio17";
			function = "gpio";
			drive-strength = <16>;
			bias-disable;
		};

		sw-ctrl-pins {
			pins = "gpio18";
			function = "gpio";
			bias-pull-down;
		};
	};

	i2c4_default: i2c4-default-state {
		pins = "gpio48", "gpio49";
		function = "gpio";
		drive-strength = <2>;
		bias-pull-up;
	};

	i2c5_default: i2c5-default-state {
		pins = "gpio52", "gpio53";
		function = "gpio";
		drive-strength = <2>;
		bias-pull-up;
	};

	wlan_en: wlan-en-state {
		pins = "gpio16";
		function = "gpio";
		drive-strength = <8>;
		bias-pull-down;
	};
};

&uart14 {
	status = "okay";

	bluetooth {
		compatible = "qcom,wcn7850-bt";

		vddrfacmn-supply = <&vreg_pmu_rfa_cmn>;
		vddaon-supply = <&vreg_pmu_aon_0p59>;
		vddwlcx-supply = <&vreg_pmu_wlcx_0p8>;
		vddwlmx-supply = <&vreg_pmu_wlmx_0p85>;
		vddrfa0p8-supply = <&vreg_pmu_rfa_0p8>;
		vddrfa1p2-supply = <&vreg_pmu_rfa_1p2>;
		vddrfa1p8-supply = <&vreg_pmu_rfa_1p8>;

		max-speed = <3200000>;
	};
};

&uart15 {
	status = "okay";
};

&ufs_mem_hc {
	reset-gpios = <&tlmm 210 GPIO_ACTIVE_LOW>;

	vcc-supply = <&vreg_l17b_2p5>;
	vcc-max-microamp = <1300000>;
	vccq-supply = <&vreg_l1c_1p2>;
	vccq-max-microamp = <1200000>;

	status = "okay";
};

&ufs_mem_phy {
	vdda-phy-supply = <&vreg_l1d_0p9>;
	vdda-pll-supply = <&vreg_l3i_1p2>;

	status = "okay";
};

&usb_1 {
	dr_mode = "peripheral";

	status = "okay";
};

&usb_1_hsphy {
	vdd-supply = <&vreg_l1i_0p88>;
	vdda12-supply = <&vreg_l3i_1p2>;

	phys = <&pm8550b_eusb2_repeater>;

	status = "okay";
};

&usb_dp_qmpphy {
	vdda-phy-supply = <&vreg_l3i_1p2>;
	vdda-pll-supply = <&vreg_l3g_0p91>;

	orientation-switch;

	status = "okay";
};

&xo_board {
	clock-frequency = <76800000>;
};
